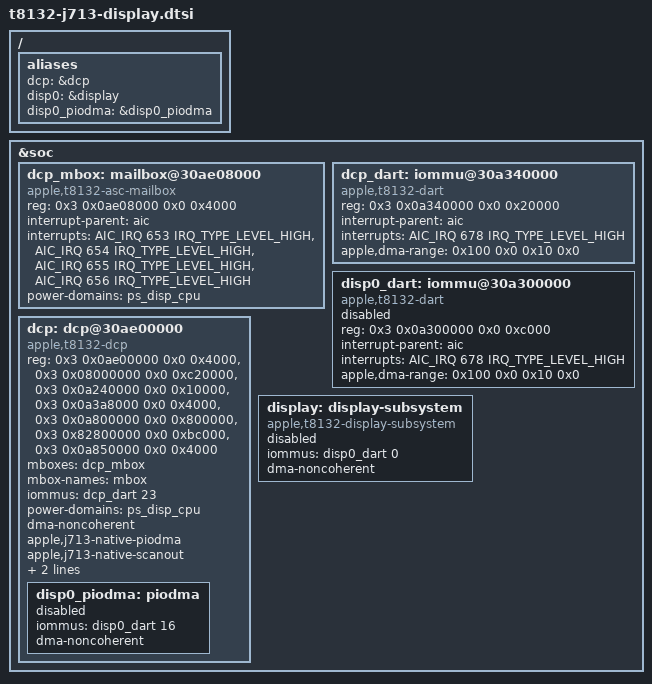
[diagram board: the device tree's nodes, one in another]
// SPDX-License-Identifier: GPL-2.0+ OR MIT
/*
 * Apple MacBook Air (13-inch, M4) internal display coprocessor (DCP).
 *
 * Node structure and values match the cleanroom J713 live device tree.
 * The DCP, its mailbox and both display DARTs are live when Linux starts:
 * the DART driver leaves the DARTs untouched until apple_dart.j713_dcp or
 * apple_dart.j713_display is set and the device re-probed, and the DCP
 * common Apple display driver (appledrm) adopts the inherited session after
 * guarded DART admission; no display lifecycle sysfs triggers are required.
 *
 * The boot loader completes these nodes. On dcp it publishes
 * apple,firmware-uuid, -version and -compat and the memory-region list of
 * DCP firmware reservations (apple,asc-mem, no-map, with iommu-addresses,
 * plus one apple,dcp-os-log region). After validating the inherited
 * frontend mappings it adds memory-region and apple,j713-inherited-mappings
 * to piodma and display-subsystem and enables them and disp0_dart.
 * apple,j713-native-piodma and apple,j713-native-scanout opt in to that.
 * The DCP, PIODMA and scanout paths use non-coherent DMA only, so those
 * nodes are marked dma-noncoherent.
 * The DART driver also reads the ADT through the loader's phram "adt"
 * region. Without that handoff the DCP and frontend are refused.
 *
 * Copyright The Asahi Linux Contributors
 */

/ {
	aliases {
		dcp = &dcp;
		disp0 = &display;
		disp0_piodma = &disp0_piodma;
	};
};

&soc {
	dcp_mbox: mailbox@30ae08000 {
		compatible = "apple,t8132-asc-mailbox", "apple,asc-mailbox-v4";
		reg = <0x3 0x0ae08000 0x0 0x4000>;
		interrupt-parent = <&aic>;
		interrupts = <AIC_IRQ 653 IRQ_TYPE_LEVEL_HIGH>,
			     <AIC_IRQ 654 IRQ_TYPE_LEVEL_HIGH>,
			     <AIC_IRQ 655 IRQ_TYPE_LEVEL_HIGH>,
			     <AIC_IRQ 656 IRQ_TYPE_LEVEL_HIGH>;
		interrupt-names = "send-empty", "send-not-empty",
				  "recv-empty", "recv-not-empty";
		power-domains = <&ps_disp_cpu>;
		#mbox-cells = <0>;
	};

	/* DCP firmware DART: SID23. */
	dcp_dart: iommu@30a340000 {
		compatible = "apple,t8132-dart", "apple,t8110-dart";
		reg = <0x3 0x0a340000 0x0 0x20000>;
		interrupt-parent = <&aic>;
		interrupts = <AIC_IRQ 678 IRQ_TYPE_LEVEL_HIGH>;
		#iommu-cells = <1>;
		apple,dma-range = <0x100 0x0 0x10 0x0>;
	};

	/* Display frontend DART: SID0 scanout, SID16 PIODMA. */
	disp0_dart: iommu@30a300000 {
		compatible = "apple,t8132-dart", "apple,t8110-dart";
		reg = <0x3 0x0a300000 0x0 0xc000>;
		interrupt-parent = <&aic>;
		interrupts = <AIC_IRQ 678 IRQ_TYPE_LEVEL_HIGH>;
		#iommu-cells = <1>;
		apple,dma-range = <0x100 0x0 0x10 0x0>;
		status = "disabled"; /* Enabled by the loader. */
	};

	dcp: dcp@30ae00000 {
		compatible = "apple,t8132-dcp";
		reg = <0x3 0x0ae00000 0x0 0x4000>,
		      <0x3 0x08000000 0x0 0xc20000>,
		      <0x3 0x0a240000 0x0 0x10000>,
		      <0x3 0x0a3a8000 0x0 0x4000>,
		      <0x3 0x0a800000 0x0 0x800000>,
		      <0x3 0x82800000 0x0 0xbc000>,
		      <0x3 0x0a850000 0x0 0x4000>;
		reg-names = "coproc", "disp-0", "disp-1", "disp-2", "disp-3",
			    "disp-4", "iop-vbar";
		mboxes = <&dcp_mbox>;
		mbox-names = "mbox";
		iommus = <&dcp_dart 23>;
		power-domains = <&ps_disp_cpu>;
		dma-noncoherent;
		apple,j713-native-piodma;
		apple,j713-native-scanout;
		/* Full 2560x1664 panel including the notch rows, 224 ppi. */
		apple,panel-width-mm = <290>;
		apple,panel-height-mm = <188>;
		#address-cells = <2>;
		#size-cells = <2>;

		disp0_piodma: piodma {
			iommus = <&disp0_dart 16>;
			dma-noncoherent;
			status = "disabled"; /* Enabled by the loader. */
		};
	};

	display: display-subsystem {
		compatible = "apple,t8132-display-subsystem", "apple,t8132-display-diagnostics";
		iommus = <&disp0_dart 0>;
		dma-noncoherent;
		status = "disabled"; /* Enabled by the loader. */
	};
};

/*
 * The shared J713 power-domain policy leaves the running display domains
 * firmware-owned. Native display adoption does not register a second genpd
 * owner or change their hardware state.
 */
